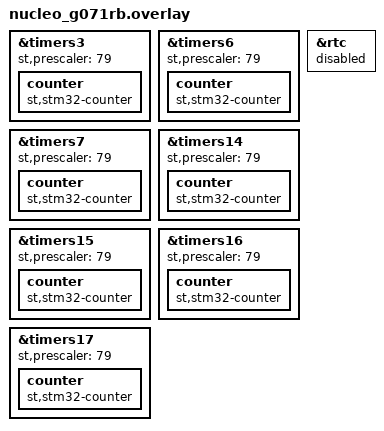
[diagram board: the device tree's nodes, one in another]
&timers3 {
	st,prescaler = <79>;
	counter {
		compatible = "st,stm32-counter";
		status = "okay";
	};
};

&timers6 {
	st,prescaler = <79>;
	counter {
		compatible = "st,stm32-counter";
		status = "okay";
	};
};

&timers7 {
	st,prescaler = <79>;
	counter {
		compatible = "st,stm32-counter";
		status = "okay";
	};
};

&timers14 {
	st,prescaler = <79>;
	status = "okay";
	counter {
		compatible = "st,stm32-counter";
		status = "okay";
	};
};

&timers15 {
	st,prescaler = <79>;
	status = "okay";
	counter {
		compatible = "st,stm32-counter";
		status = "okay";
	};
};

&timers16 {
	st,prescaler = <79>;
	status = "okay";
	counter {
		compatible = "st,stm32-counter";
		status = "okay";
	};
};

&timers17 {
	st,prescaler = <79>;
	status = "okay";
	counter {
		compatible = "st,stm32-counter";
		status = "okay";
	};
};

&rtc {
	status = "disabled";
};
